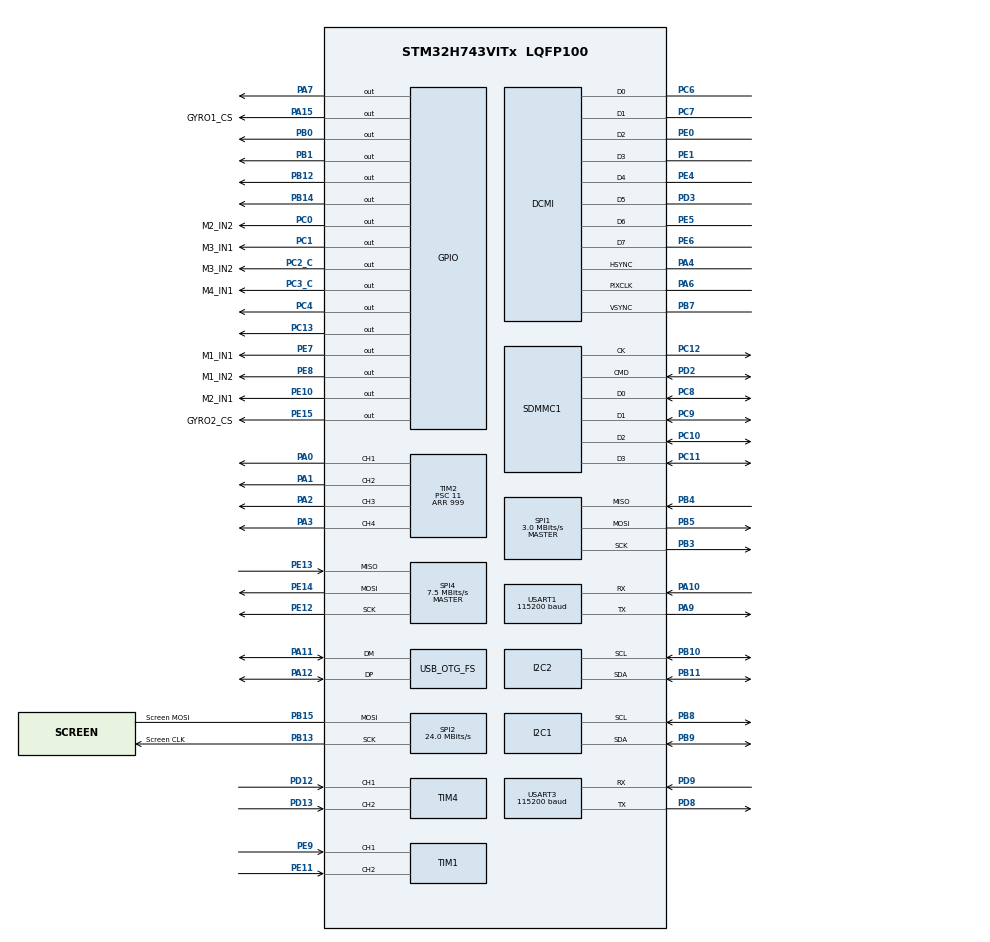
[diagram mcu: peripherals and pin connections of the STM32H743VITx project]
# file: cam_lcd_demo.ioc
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CORTEX_M7.CPU_DCache=Enabled
CORTEX_M7.CPU_ICache=Enabled
DCMI.JPEGMode=DCMI_JPEG_DISABLE
DCMI.PCKPolarity=DCMI_PCKPOLARITY_RISING
Dma.DCMI.0.Direction=DMA_PERIPH_TO_MEMORY
Dma.DCMI.0.EventEnable=DISABLE
Dma.DCMI.0.FIFOMode=DMA_FIFOMODE_ENABLE
Dma.DCMI.0.FIFOThreshold=DMA_FIFO_THRESHOLD_HALFFULL
Dma.DCMI.0.Instance=DMA1_Stream0
Dma.DCMI.0.MemBurst=DMA_MBURST_SINGLE
Dma.DCMI.0.MemDataAlignment=DMA_MDATAALIGN_WORD
Dma.DCMI.0.MemInc=DMA_MINC_ENABLE
Dma.DCMI.0.Mode=DMA_CIRCULAR
Dma.DCMI.0.PeriphBurst=DMA_PBURST_SINGLE
Dma.DCMI.0.PeriphDataAlignment=DMA_PDATAALIGN_WORD
Dma.DCMI.0.PeriphInc=DMA_PINC_DISABLE
Dma.DCMI.0.Polarity=HAL_DMAMUX_REQ_GEN_RISING
Dma.DCMI.0.Priority=DMA_PRIORITY_MEDIUM
Dma.DCMI.0.RequestNumber=1
Dma.DCMI.0.SignalID=NONE
Dma.DCMI.0.SyncEnable=DISABLE
Dma.DCMI.0.SyncPolarity=HAL_DMAMUX_SYNC_NO_EVENT
Dma.DCMI.0.SyncRequestNumber=1
Dma.DCMI.0.SyncSignalID=NONE
Dma.Request0=DCMI
FREERTOS.Tasks01=defaultTask,24,128,StartDefaultTask,Default,NULL,Dynamic,NULL,NULL
I2C1.Timing=0x307075B1
I2C2.Timing=0x307075B1
Mcu.Family=STM32H7
Mcu.Name=STM32H743VITx
Mcu.Package=LQFP100
NVIC.DCMI_IRQn=true\:5\:0\:true\:false\:true\:true\:true\:true\:true
NVIC.DMA1_Stream0_IRQn=true\:5\:0\:true\:false\:true\:true\:false\:true\:true
NVIC.I2C1_ER_IRQn=true\:5\:0\:false\:false\:true\:true\:true\:true\:true
NVIC.I2C1_EV_IRQn=true\:5\:0\:false\:false\:true\:true\:true\:true\:true
NVIC.I2C2_ER_IRQn=true\:5\:0\:false\:false\:true\:true\:true\:true\:true
NVIC.I2C2_EV_IRQn=true\:5\:0\:false\:false\:true\:true\:true\:true\:true
NVIC.OTG_FS_IRQn=true\:5\:0\:false\:false\:true\:true\:true\:true\:true
NVIC.PriorityGroup=NVIC_PRIORITYGROUP_4
NVIC.TIM6_DAC_IRQn=true\:15\:0\:false\:false\:true\:false\:false\:false\:true
NVIC.TimeBase=TIM6_DAC_IRQn
NVIC.TimeBaseIP=TIM6
NVIC.USART1_IRQn=true\:5\:0\:false\:false\:true\:true\:true\:true\:true
NVIC.USART3_IRQn=true\:5\:0\:false\:false\:true\:true\:true\:true\:true
PA0.Signal=S_TIM2_CH1_ETR
PA1.Signal=S_TIM2_CH2
PA10.Mode=Asynchronous
PA10.Signal=USART1_RX
PA11.Mode=Device_Only
PA11.Signal=USB_OTG_FS_DM
PA12.Mode=Device_Only
PA12.Signal=USB_OTG_FS_DP
PA13\ (JTMS/SWDIO).Mode=Trace_Asynchronous_SW
PA13\ (JTMS/SWDIO).Signal=DEBUG_JTMS-SWDIO
PA14\ (JTCK/SWCLK).Mode=Trace_Asynchronous_SW
PA14\ (JTCK/SWCLK).Signal=DEBUG_JTCK-SWCLK
PA15\ (JTDI).GPIO_Label=GYRO1_CS
PA15\ (JTDI).Signal=GPIO_Output
PA2.Signal=S_TIM2_CH3
PA3.Signal=S_TIM2_CH4
PA4.GPIO_PuPd=GPIO_PULLUP
PA4.GPIO_Speed=GPIO_SPEED_FREQ_VERY_HIGH
PA4.Mode=Slave_8_bits_External_Synchro
PA4.Signal=DCMI_HSYNC
PA6.GPIO_PuPd=GPIO_PULLUP
PA6.GPIO_Speed=GPIO_SPEED_FREQ_VERY_HIGH
PA6.Mode=Slave_8_bits_External_Synchro
PA6.Signal=DCMI_PIXCLK
PA7.GPIO_PuPd=GPIO_PULLUP
PA7.GPIO_Speed=GPIO_SPEED_FREQ_VERY_HIGH
PA7.PinState=GPIO_PIN_RESET
PA7.Signal=GPIO_Output
PA8.Signal=RCC_MCO_1
PA9.Mode=Asynchronous
PA9.Signal=USART1_TX
PB0.Signal=GPIO_Output
PB1.GPIO_PuPd=GPIO_PULLUP
PB1.GPIO_Speed=GPIO_SPEED_FREQ_VERY_HIGH
PB1.PinState=GPIO_PIN_SET
PB1.Signal=GPIO_Output
PB10.GPIO_Pu=GPIO_PULLUP
PB10.Mode=I2C
PB10.Signal=I2C2_SCL
PB11.GPIO_Pu=GPIO_PULLUP
PB11.Mode=I2C
PB11.Signal=I2C2_SDA
PB12.GPIO_PuPd=GPIO_PULLUP
PB12.GPIO_Speed=GPIO_SPEED_FREQ_VERY_HIGH
PB12.PinState=GPIO_PIN_SET
PB12.Signal=GPIO_Output
PB13.GPIO_Label=Screen CLK
PB13.Mode=Simplex_Bidirectional_Master
PB13.Signal=SPI2_SCK
PB14.GPIO_PuPd=GPIO_PULLUP
PB14.GPIO_Speed=GPIO_SPEED_FREQ_VERY_HIGH
PB14.PinState=GPIO_PIN_SET
PB14.Signal=GPIO_Output
PB15.GPIO_Label=Screen MOSI
PB15.Mode=Simplex_Bidirectional_Master
PB15.Signal=SPI2_MOSI
PB3\ (JTDO/TRACESWO).Mode=Full_Duplex_Master
PB3\ (JTDO/TRACESWO).Signal=SPI1_SCK
PB4\ (NJTRST).Mode=Full_Duplex_Master
PB4\ (NJTRST).Signal=SPI1_MISO
PB5.Mode=Full_Duplex_Master
PB5.Signal=SPI1_MOSI
PB7.GPIO_PuPd=GPIO_PULLUP
PB7.GPIO_Speed=GPIO_SPEED_FREQ_VERY_HIGH
PB7.Mode=Slave_8_bits_External_Synchro
PB7.Signal=DCMI_VSYNC
PB8.Mode=I2C
PB8.Signal=I2C1_SCL
PB9.Mode=I2C
PB9.Signal=I2C1_SDA
PC0.GPIO_Label=M2_IN2
PC0.Signal=GPIO_Output
PC1.GPIO_Label=M3_IN1
PC1.Signal=GPIO_Output
PC10.Mode=SD_4_bits_Wide_bus
PC10.Signal=SDMMC1_D2
PC11.Mode=SD_4_bits_Wide_bus
PC11.Signal=SDMMC1_D3
PC12.Mode=SD_4_bits_Wide_bus
PC12.Signal=SDMMC1_CK
PC13.Signal=GPIO_Output
PC2_C.GPIO_Label=M3_IN2
PC2_C.Signal=GPIO_Output
PC3_C.GPIO_Label=M4_IN1
PC3_C.Signal=GPIO_Output
PC4.GPIO_PuPd=GPIO_PULLUP
PC4.GPIO_Speed=GPIO_SPEED_FREQ_VERY_HIGH
PC4.PinState=GPIO_PIN_SET
PC4.Signal=GPIO_Output
PC6.GPIO_PuPd=GPIO_PULLUP
PC6.GPIO_Speed=GPIO_SPEED_FREQ_VERY_HIGH
PC6.Mode=Slave_8_bits_External_Synchro
PC6.Signal=DCMI_D0
PC7.GPIO_PuPd=GPIO_PULLUP
PC7.GPIO_Speed=GPIO_SPEED_FREQ_VERY_HIGH
PC7.Mode=Slave_8_bits_External_Synchro
PC7.Signal=DCMI_D1
PC8.Mode=SD_4_bits_Wide_bus
PC8.Signal=SDMMC1_D0
PC9.Mode=SD_4_bits_Wide_bus
PC9.Signal=SDMMC1_D1
PD12.Signal=S_TIM4_CH1
PD13.Signal=S_TIM4_CH2
PD2.Mode=SD_4_bits_Wide_bus
PD2.Signal=SDMMC1_CMD
PD3.GPIO_PuPd=GPIO_PULLUP
PD3.GPIO_Speed=GPIO_SPEED_FREQ_VERY_HIGH
PD3.Mode=Slave_8_bits_External_Synchro
PD3.Signal=DCMI_D5
PD8.Mode=Asynchronous
PD8.Signal=USART3_TX
PD9.Mode=Asynchronous
PD9.Signal=USART3_RX
PE0.GPIO_PuPd=GPIO_PULLUP
PE0.GPIO_Speed=GPIO_SPEED_FREQ_VERY_HIGH
PE0.Mode=Slave_8_bits_External_Synchro
PE0.Signal=DCMI_D2
PE1.GPIO_PuPd=GPIO_PULLUP
PE1.GPIO_Speed=GPIO_SPEED_FREQ_VERY_HIGH
PE1.Mode=Slave_8_bits_External_Synchro
PE1.Signal=DCMI_D3
PE10.GPIO_Label=M2_IN1
PE10.Signal=GPIO_Output
PE11.Signal=S_TIM1_CH2
PE12.Mode=Full_Duplex_Master
PE12.Signal=SPI4_SCK
PE13.Mode=Full_Duplex_Master
PE13.Signal=SPI4_MISO
PE14.Mode=Full_Duplex_Master
PE14.Signal=SPI4_MOSI
PE15.GPIO_Label=GYRO2_CS
PE15.Signal=GPIO_Output
PE4.GPIO_PuPd=GPIO_PULLUP
PE4.GPIO_Speed=GPIO_SPEED_FREQ_VERY_HIGH
PE4.Mode=Slave_8_bits_External_Synchro
PE4.Signal=DCMI_D4
PE5.GPIO_PuPd=GPIO_PULLUP
PE5.GPIO_Speed=GPIO_SPEED_FREQ_VERY_HIGH
PE5.Mode=Slave_8_bits_External_Synchro
PE5.Signal=DCMI_D6
PE6.GPIO_PuPd=GPIO_PULLUP
PE6.GPIO_Speed=GPIO_SPEED_FREQ_VERY_HIGH
PE6.Mode=Slave_8_bits_External_Synchro
PE6.Signal=DCMI_D7
PE7.GPIO_Label=M1_IN1
PE7.Signal=GPIO_Output
PE8.GPIO_Label=M1_IN2
PE8.Signal=GPIO_Output
PE9.Signal=S_TIM1_CH1
PH0-OSC_IN\ (PH0).Mode=HSE-External-Clock-Source
PH0-OSC_IN\ (PH0).Signal=RCC_OSC_IN
PH1-OSC_OUT\ (PH1).Signal=RCC_OSC_OUT
ProjectManager.HeapSize=0x800
ProjectManager.StackSize=0x1000
ProjectManager.TargetToolchain=CMake
RCC.48MHZClocksFreq_Value=48000000
RCC.ADCFreq_Value=50390625
RCC.AHBFreq_Value=240000000
RCC.APB1Freq_Value=120000000
RCC.APB1TimFreq_Value=240000000
RCC.APB2Freq_Value=120000000
RCC.APB2TimFreq_Value=240000000
RCC.APB3Freq_Value=120000000
RCC.APB4Freq_Value=120000000
RCC.CKPERSourceSelection=RCC_CLKPSOURCE_HSE
RCC.CortexFreq_Value=480000000
RCC.D1PPRE=RCC_APB3_DIV2
RCC.D2PPRE1=RCC_APB1_DIV2
RCC.D2PPRE2=RCC_APB2_DIV2
RCC.D3PPRE=RCC_APB4_DIV2
RCC.DIVM1=5
RCC.DIVN1=192
RCC.DIVQ1=20
RCC.DIVR1=2
RCC.HCLKFreq_Value=240000000
RCC.HPRE=RCC_HCLK_DIV2
RCC.HSE_VALUE=25000000
RCC.HSI_VALUE=64000000
RCC.PLLFRACN=0
RCC.PLLSourceVirtual=RCC_PLLSOURCE_HSE
RCC.PWR_Regulator_Voltage_Scale=PWR_REGULATOR_VOLTAGE_SCALE0
RCC.RCC_MCO1Source=RCC_MCO1SOURCE_HSE
RCC.SYSCLKFreq_VALUE=480000000
RCC.SYSCLKSource=RCC_SYSCLKSOURCE_PLLCLK
RCC.SYSCLKSourceVirtual=RCC_SYSCLKSOURCE_PLLCLK
RCC.USBCLockSelection=RCC_USBCLKSOURCE_PLL
RCC.USBFreq_Value=48000000
SH.S_TIM1_CH1.0=TIM1_CH1,Encoder_Interface
SH.S_TIM1_CH2.0=TIM1_CH2,Encoder_Interface
SH.S_TIM2_CH1_ETR.0=TIM2_CH1,PWM Generation1 CH1
SH.S_TIM2_CH2.0=TIM2_CH2,PWM Generation2 CH2
SH.S_TIM2_CH3.0=TIM2_CH3,PWM Generation3 CH3
SH.S_TIM2_CH4.0=TIM2_CH4,PWM Generation4 CH4
SH.S_TIM4_CH1.0=TIM4_CH1,Encoder_Interface
SH.S_TIM4_CH2.0=TIM4_CH2,Encoder_Interface
SPI1.BaudRatePrescaler=SPI_BAUDRATEPRESCALER_16
SPI1.CalculateBaudRate=3.0 MBits/s
SPI1.DataSize=SPI_DATASIZE_8BIT
SPI1.Direction=SPI_DIRECTION_2LINES
SPI1.Mode=SPI_MODE_MASTER
SPI1.VirtualMode=Full-Duplex_Master
SPI1.VirtualType=VM_MASTER
SPI2.CalculateBaudRate=24.0 MBits/s
SPI2.DataSize=SPI_DATASIZE_8BIT
SPI2.Direction=SPI_DIRECTION_1LINE
SPI2.Mode=SPI_MODE_MASTER
SPI2.VirtualType=VM_MASTER
SPI4.BaudRatePrescaler=SPI_BAUDRATEPRESCALER_16
SPI4.CalculateBaudRate=7.5 MBits/s
SPI4.DataSize=SPI_DATASIZE_8BIT
SPI4.Direction=SPI_DIRECTION_2LINES
SPI4.Mode=SPI_MODE_MASTER
SPI4.VirtualMode=Full-Duplex_Master
SPI4.VirtualType=VM_MASTER
TIM2.AutoReloadPreload=TIM_AUTORELOAD_PRELOAD_DISABLE
TIM2.Channel-PWM\ Generation1\ CH1=TIM_CHANNEL_1
TIM2.Channel-PWM\ Generation2\ CH2=TIM_CHANNEL_2
TIM2.Channel-PWM\ Generation3\ CH3=TIM_CHANNEL_3
TIM2.Channel-PWM\ Generation4\ CH4=TIM_CHANNEL_4
TIM2.ClockDivision=TIM_CLOCKDIVISION_DIV1
TIM2.CounterMode=TIM_COUNTERMODE_UP
TIM2.Period=999
TIM2.Prescaler=11
USART1.BaudRate=115200
USART1.Parity=PARITY_NONE
USART1.StopBits=STOPBITS_1
USART1.VirtualMode-Asynchronous=VM_ASYNC
USART1.WordLength=WORDLENGTH_8B
USART3.BaudRate=115200
USART3.FIFOMode=FIFOMODE_DISABLE
USART3.OneBitSampling=UART_ONE_BIT_SAMPLE_ENABLE
USART3.Parity=PARITY_NONE
USART3.StopBits=STOPBITS_1
USART3.VirtualMode-Asynchronous=VM_ASYNC
USART3.WordLength=WORDLENGTH_8B
USB_DEVICE.CLASS_NAME_FS=CDC
USB_DEVICE.USBD_LPM_ENABLED-CDC_FS=0
USB_DEVICE.VirtualMode-CDC_FS=Cdc
USB_DEVICE.VirtualModeFS=Cdc_FS
USB_OTG_FS.VirtualMode=Device_Only
VP_FREERTOS_VS_CMSIS_V2.Mode=CMSIS_V2
VP_MEMORYMAP_VS_MEMORYMAP.Mode=CurAppReg
VP_SYS_VS_tim6.Mode=TIM6
VP_TIM2_VS_ClockSourceINT.Mode=Internal
VP_USB_DEVICE_VS_USB_DEVICE_CDC_FS.Mode=CDC_FS
board=custom

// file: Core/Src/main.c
/* USER CODE BEGIN Header */
/**
  ******************************************************************************
  * @file           : main.c
  * @brief          : ��10 ��Ļ��ʾ����ͷ (OV2640 RGB565 -> 1.44�� LCD)
  ******************************************************************************
  */
/* USER CODE END Header */
#include "main.h"
#include "FreeRTOS.h"
#include "cmsis_os2.h"
#include "usb_device.h"

/* USER CODE BEGIN Includes */
#include "usb_vcp.h"
#include "cam_lcd.h"
#include "app_config.h"
#include "vision_task.h"
/* USER CODE END Includes */

DCMI_HandleTypeDef hdcmi;
DMA_HandleTypeDef hdma_dcmi;

I2C_HandleTypeDef hi2c1;
I2C_HandleTypeDef hi2c2;

SD_HandleTypeDef hsd1;

SPI_HandleTypeDef hspi1;
SPI_HandleTypeDef hspi2;
SPI_HandleTypeDef hspi4;

TIM_HandleTypeDef htim1;
TIM_HandleTypeDef htim2;
TIM_HandleTypeDef htim4;

UART_HandleTypeDef huart1;
UART_HandleTypeDef huart3;

/* Definitions for defaultTask */
osThreadId_t defaultTaskHandle;
const osThreadAttr_t defaultTask_attributes = {
  .name = "defaultTask",
  .stack_size = 1024 * 8,
  .priority = (osPriority_t) osPriorityNormal,
};

void SystemClock_Config(void);
static void MX_GPIO_Init(void);
static void MX_DMA_Init(void);
static void MX_I2C1_Init(void);
static void MX_I2C2_Init(void);
static void MX_SPI1_Init(void);
static void MX_SPI4_Init(void);
static void MX_TIM1_Init(void);
static void MX_TIM2_Init(void);
static void MX_TIM4_Init(void);
static void MX_USART1_UART_Init(void);
static void MX_USART3_UART_Init(void);
static void MX_DCMI_Init(void);
static void MX_SDMMC1_SD_Init(void);
static void MX_SPI2_Init(void);
void StartDefaultTask(void *argument);

int main(void)
{

  /* Enable the CPU Cache */

  /* Enable I-Cache---------------------------------------------------------*/
  SCB_EnableICache();

  /* Enable D-Cache---------------------------------------------------------*/
  SCB_EnableDCache();

  /* MCU Configuration--------------------------------------------------------*/

  /* Reset of all peripherals, Initializes the Flash interface and the Systick. */
  HAL_Init();

  /* Configure the system clock */
  SystemClock_Config();

  /* Initialize all configured peripherals */
  MX_GPIO_Init();
  MX_DMA_Init();
  MX_I2C1_Init();
  MX_I2C2_Init();
  MX_SPI1_Init();
  MX_SPI4_Init();
  MX_TIM1_Init();
  MX_TIM2_Init();
  MX_TIM4_Init();
  MX_USART1_UART_Init();
  MX_USART3_UART_Init();
  MX_DCMI_Init();
  MX_SDMMC1_SD_Init();
  MX_SPI2_Init();

  /* Init scheduler */
  osKernelInitialize();

  /* USER CODE BEGIN RTOS_QUEUES */
  if (!UsbVcp_Init())
  {
    Error_Handler();
  }
  /* USER CODE END RTOS_QUEUES */

  /* Create the thread(s) */
  /* creation of defaultTask */
  defaultTaskHandle = osThreadNew(StartDefaultTask, NULL, &defaultTask_attributes);

  /* Start scheduler */
  osKernelStart();

  /* We should never get here as control is now taken by the scheduler */

  /* Infinite loop */
  while (1)
  {

  }
}

void SystemClock_Config(void)
{
  RCC_OscInitTypeDef RCC_OscInitStruct = {0};
  RCC_ClkInitTypeDef RCC_ClkInitStruct = {0};

  /** Supply configuration update enable
  */
  HAL_PWREx_ConfigSupply(PWR_LDO_SUPPLY);

  /** Configure the main internal regulator output voltage
  */
  __HAL_PWR_VOLTAGESCALING_CONFIG(PWR_REGULATOR_VOLTAGE_SCALE0);

  while(!__HAL_PWR_GET_FLAG(PWR_FLAG_VOSRDY)) {}

  /** Initializes the RCC Oscillators according to the specified parameters
  * in the RCC_OscInitTypeDef structure.
  */
  RCC_OscInitStruct.OscillatorType = RCC_OSCILLATORTYPE_HSE;
  RCC_OscInitStruct.HSEState = RCC_HSE_BYPASS;
  RCC_OscInitStruct.PLL.PLLState = RCC_PLL_ON;
  RCC_OscInitStruct.PLL.PLLSource = RCC_PLLSOURCE_HSE;
  RCC_OscInitStruct.PLL.PLLM = 5;
  RCC_OscInitStruct.PLL.PLLN = 192;
  RCC_OscInitStruct.PLL.PLLP = 2;
  RCC_OscInitStruct.PLL.PLLQ = 20;
  RCC_OscInitStruct.PLL.PLLR = 2;
  RCC_OscInitStruct.PLL.PLLRGE = RCC_PLL1VCIRANGE_2;
  RCC_OscInitStruct.PLL.PLLVCOSEL = RCC_PLL1VCOWIDE;
  RCC_OscInitStruct.PLL.PLLFRACN = 0;
  if (HAL_RCC_OscConfig(&RCC_OscInitStruct) != HAL_OK)
  {
    Error_Handler();
  }

  /** Initializes the CPU, AHB and APB buses clocks
  */
  RCC_ClkInitStruct.ClockType = RCC_CLOCKTYPE_HCLK|RCC_CLOCKTYPE_SYSCLK
                              |RCC_CLOCKTYPE_PCLK1|RCC_CLOCKTYPE_PCLK2
                              |RCC_CLOCKTYPE_D3PCLK1|RCC_CLOCKTYPE_D1PCLK1;
  RCC_ClkInitStruct.SYSCLKSource = RCC_SYSCLKSOURCE_PLLCLK;
  RCC_ClkInitStruct.SYSCLKDivider = RCC_SYSCLK_DIV1;
  RCC_ClkInitStruct.AHBCLKDivider = RCC_HCLK_DIV2;
  RCC_ClkInitStruct.APB3CLKDivider = RCC_APB3_DIV2;
  RCC_ClkInitStruct.APB1CLKDivider = RCC_APB1_DIV2;
  RCC_ClkInitStruct.APB2CLKDivider = RCC_APB2_DIV2;
  RCC_ClkInitStruct.APB4CLKDivider = RCC_APB4_DIV2;

  if (HAL_RCC_ClockConfig(&RCC_ClkInitStruct, FLASH_LATENCY_4) != HAL_OK)
  {
    Error_Handler();
  }
}

static void MX_DCMI_Init(void)
{

  hdcmi.Instance = DCMI;
  hdcmi.Init.SynchroMode = DCMI_SYNCHRO_HARDWARE;
  hdcmi.Init.PCKPolarity = DCMI_PCKPOLARITY_RISING;
  hdcmi.Init.VSPolarity = DCMI_VSPOLARITY_LOW;
  hdcmi.Init.HSPolarity = DCMI_HSPOLARITY_LOW;
  hdcmi.Init.CaptureRate = DCMI_CR_ALL_FRAME;
  hdcmi.Init.ExtendedDataMode = DCMI_EXTEND_DATA_8B;
  hdcmi.Init.JPEGMode = DCMI_JPEG_DISABLE;
  hdcmi.Init.ByteSelectMode = DCMI_BSM_ALL;
  hdcmi.Init.ByteSelectStart = DCMI_OEBS_ODD;
  hdcmi.Init.LineSelectMode = DCMI_LSM_ALL;
  hdcmi.Init.LineSelectStart = DCMI_OELS_ODD;
  if (HAL_DCMI_Init(&hdcmi) != HAL_OK)
  {
    Error_Handler();
  }

}

static void MX_I2C1_Init(void)
{

  hi2c1.Instance = I2C1;
  hi2c1.Init.Timing = 0x307075B1;
  hi2c1.Init.OwnAddress1 = 0;
  hi2c1.Init.AddressingMode = I2C_ADDRESSINGMODE_7BIT;
  hi2c1.Init.DualAddressMode = I2C_DUALADDRESS_DISABLE;
  hi2c1.Init.OwnAddress2 = 0;
  hi2c1.Init.OwnAddress2Masks = I2C_OA2_NOMASK;
  hi2c1.Init.GeneralCallMode = I2C_GENERALCALL_DISABLE;
  hi2c1.Init.NoStretchMode = I2C_NOSTRETCH_DISABLE;
  if (HAL_I2C_Init(&hi2c1) != HAL_OK)
  {
    Error_Handler();
  }

  /** Configure Analogue filter
  */
  if (HAL_I2CEx_ConfigAnalogFilter(&hi2c1, I2C_ANALOGFILTER_ENABLE) != HAL_OK)
  {
    Error_Handler();
  }

  /** Configure Digital filter
  */
  if (HAL_I2CEx_ConfigDigitalFilter(&hi2c1, 0) != HAL_OK)
  {
    Error_Handler();
  }

}

static void MX_I2C2_Init(void)
{

  hi2c2.Instance = I2C2;
  hi2c2.Init.Timing = 0x307075B1;
  hi2c2.Init.OwnAddress1 = 0;
  hi2c2.Init.AddressingMode = I2C_ADDRESSINGMODE_7BIT;
  hi2c2.Init.DualAddressMode = I2C_DUALADDRESS_DISABLE;
  hi2c2.Init.OwnAddress2 = 0;
  hi2c2.Init.OwnAddress2Masks = I2C_OA2_NOMASK;
  hi2c2.Init.GeneralCallMode = I2C_GENERALCALL_DISABLE;
  hi2c2.Init.NoStretchMode = I2C_NOSTRETCH_DISABLE;
  if (HAL_I2C_Init(&hi2c2) != HAL_OK)
  {
    Error_Handler();
  }

  /** Configure Analogue filter
  */
  if (HAL_I2CEx_ConfigAnalogFilter(&hi2c2, I2C_ANALOGFILTER_ENABLE) != HAL_OK)
  {
    Error_Handler();
  }

  /** Configure Digital filter
  */
  if (HAL_I2CEx_ConfigDigitalFilter(&hi2c2, 0) != HAL_OK)
  {
    Error_Handler();
  }

}

static void MX_SDMMC1_SD_Init(void)
{

  hsd1.Instance = SDMMC1;
  hsd1.Init.ClockEdge = SDMMC_CLOCK_EDGE_RISING;
  hsd1.Init.ClockPowerSave = SDMMC_CLOCK_POWER_SAVE_DISABLE;
  hsd1.Init.BusWide = SDMMC_BUS_WIDE_4B;
  hsd1.Init.HardwareFlowControl = SDMMC_HARDWARE_FLOW_CONTROL_DISABLE;
  hsd1.Init.ClockDiv = 0;
  if (HAL_SD_Init(&hsd1) != HAL_OK)
  {
    Error_Handler();
  }

}

static void MX_SPI1_Init(void)
{

  /* SPI1 parameter configuration*/
  hspi1.Instance = SPI1;
  hspi1.Init.Mode = SPI_MODE_MASTER;
  hspi1.Init.Direction = SPI_DIRECTION_2LINES;
  hspi1.Init.DataSize = SPI_DATASIZE_8BIT;
  hspi1.Init.CLKPolarity = SPI_POLARITY_LOW;
  hspi1.Init.CLKPhase = SPI_PHASE_1EDGE;
  hspi1.Init.NSS = SPI_NSS_SOFT;
  hspi1.Init.BaudRatePrescaler = SPI_BAUDRATEPRESCALER_16;
  hspi1.Init.FirstBit = SPI_FIRSTBIT_MSB;
  hspi1.Init.TIMode = SPI_TIMODE_DISABLE;
  hspi1.Init.CRCCalculation = SPI_CRCCALCULATION_DISABLE;
  hspi1.Init.CRCPolynomial = 0x0;
  hspi1.Init.NSSPMode = SPI_NSS_PULSE_ENABLE;
  hspi1.Init.NSSPolarity = SPI_NSS_POLARITY_LOW;
  hspi1.Init.FifoThreshold = SPI_FIFO_THRESHOLD_01DATA;
  hspi1.Init.TxCRCInitializationPattern = SPI_CRC_INITIALIZATION_ALL_ZERO_PATTERN;
  hspi1.Init.RxCRCInitializationPattern = SPI_CRC_INITIALIZATION_ALL_ZERO_PATTERN;
  hspi1.Init.MasterSSIdleness = SPI_MASTER_SS_IDLENESS_00CYCLE;
  hspi1.Init.MasterInterDataIdleness = SPI_MASTER_INTERDATA_IDLENESS_00CYCLE;
  hspi1.Init.MasterReceiverAutoSusp = SPI_MASTER_RX_AUTOSUSP_DISABLE;
  hspi1.Init.MasterKeepIOState = SPI_MASTER_KEEP_IO_STATE_DISABLE;
  hspi1.Init.IOSwap = SPI_IO_SWAP_DISABLE;
  if (HAL_SPI_Init(&hspi1) != HAL_OK)
  {
    Error_Handler();
  }

}

static void MX_SPI2_Init(void)
{

  /* SPI2 parameter configuration*/
  hspi2.Instance = SPI2;
  hspi2.Init.Mode = SPI_MODE_MASTER;
  hspi2.Init.Direction = SPI_DIRECTION_1LINE;
  hspi2.Init.DataSize = SPI_DATASIZE_8BIT;
  hspi2.Init.CLKPolarity = SPI_POLARITY_LOW;
  hspi2.Init.CLKPhase = SPI_PHASE_1EDGE;
  hspi2.Init.NSS = SPI_NSS_SOFT;
  hspi2.Init.BaudRatePrescaler = SPI_BAUDRATEPRESCALER_2;
  hspi2.Init.FirstBit = SPI_FIRSTBIT_MSB;
  hspi2.Init.TIMode = SPI_TIMODE_DISABLE;
  hspi2.Init.CRCCalculation = SPI_CRCCALCULATION_DISABLE;
  hspi2.Init.CRCPolynomial = 0x0;
  hspi2.Init.NSSPMode = SPI_NSS_PULSE_ENABLE;
  hspi2.Init.NSSPolarity = SPI_NSS_POLARITY_LOW;
  hspi2.Init.FifoThreshold = SPI_FIFO_THRESHOLD_01DATA;
  hspi2.Init.TxCRCInitializationPattern = SPI_CRC_INITIALIZATION_ALL_ZERO_PATTERN;
  hspi2.Init.RxCRCInitializationPattern = SPI_CRC_INITIALIZATION_ALL_ZERO_PATTERN;
  hspi2.Init.MasterSSIdleness = SPI_MASTER_SS_IDLENESS_00CYCLE;
  hspi2.Init.MasterInterDataIdleness = SPI_MASTER_INTERDATA_IDLENESS_00CYCLE;
  hspi2.Init.MasterReceiverAutoSusp = SPI_MASTER_RX_AUTOSUSP_DISABLE;
  hspi2.Init.MasterKeepIOState = SPI_MASTER_KEEP_IO_STATE_DISABLE;
  hspi2.Init.IOSwap = SPI_IO_SWAP_DISABLE;
  if (HAL_SPI_Init(&hspi2) != HAL_OK)
  {
    Error_Handler();
  }

}

static void MX_SPI4_Init(void)
{

  /* SPI4 parameter configuration*/
  hspi4.Instance = SPI4;
  hspi4.Init.Mode = SPI_MODE_MASTER;
  hspi4.Init.Direction = SPI_DIRECTION_2LINES;
  hspi4.Init.DataSize = SPI_DATASIZE_8BIT;
  hspi4.Init.CLKPolarity = SPI_POLARITY_LOW;
  hspi4.Init.CLKPhase = SPI_PHASE_1EDGE;
  hspi4.Init.NSS = SPI_NSS_SOFT;
  hspi4.Init.BaudRatePrescaler = SPI_BAUDRATEPRESCALER_16;
  hspi4.Init.FirstBit = SPI_FIRSTBIT_MSB;
  hspi4.Init.TIMode = SPI_TIMODE_DISABLE;
  hspi4.Init.CRCCalculation = SPI_CRCCALCULATION_DISABLE;
  hspi4.Init.CRCPolynomial = 0x0;
  hspi4.Init.NSSPMode = SPI_NSS_PULSE_ENABLE;
  hspi4.Init.NSSPolarity = SPI_NSS_POLARITY_LOW;
  hspi4.Init.FifoThreshold = SPI_FIFO_THRESHOLD_01DATA;
  hspi4.Init.TxCRCInitializationPattern = SPI_CRC_INITIALIZATION_ALL_ZERO_PATTERN;
  hspi4.Init.RxCRCInitializationPattern = SPI_CRC_INITIALIZATION_ALL_ZERO_PATTERN;
  hspi4.Init.MasterSSIdleness = SPI_MASTER_SS_IDLENESS_00CYCLE;
  hspi4.Init.MasterInterDataIdleness = SPI_MASTER_INTERDATA_IDLENESS_00CYCLE;
  hspi4.Init.MasterReceiverAutoSusp = SPI_MASTER_RX_AUTOSUSP_DISABLE;
  hspi4.Init.MasterKeepIOState = SPI_MASTER_KEEP_IO_STATE_DISABLE;
  hspi4.Init.IOSwap = SPI_IO_SWAP_DISABLE;
  if (HAL_SPI_Init(&hspi4) != HAL_OK)
  {
    Error_Handler();
  }

}

static void MX_TIM1_Init(void)
{

  TIM_Encoder_InitTypeDef sConfig = {0};
  TIM_MasterConfigTypeDef sMasterConfig = {0};

  htim1.Instance = TIM1;
  htim1.Init.Prescaler = 0;
  htim1.Init.CounterMode = TIM_COUNTERMODE_UP;
  htim1.Init.Period = 65535;
  htim1.Init.ClockDivision = TIM_CLOCKDIVISION_DIV1;
  htim1.Init.RepetitionCounter = 0;
  htim1.Init.AutoReloadPreload = TIM_AUTORELOAD_PRELOAD_DISABLE;
  sConfig.EncoderMode = TIM_ENCODERMODE_TI1;
  sConfig.IC1Polarity = TIM_ICPOLARITY_RISING;
  sConfig.IC1Selection = TIM_ICSELECTION_DIRECTTI;
  sConfig.IC1Prescaler = TIM_ICPSC_DIV1;
  sConfig.IC1Filter = 0;
  sConfig.IC2Polarity = TIM_ICPOLARITY_RISING;
  sConfig.IC2Selection = TIM_ICSELECTION_DIRECTTI;
  sConfig.IC2Prescaler = TIM_ICPSC_DIV1;
  sConfig.IC2Filter = 0;
  if (HAL_TIM_Encoder_Init(&htim1, &sConfig) != HAL_OK)
  {
    Error_Handler();
  }
  sMasterConfig.MasterOutputTrigger = TIM_TRGO_RESET;
  sMasterConfig.MasterOutputTrigger2 = TIM_TRGO2_RESET;
  sMasterConfig.MasterSlaveMode = TIM_MASTERSLAVEMODE_DISABLE;
  if (HAL_TIMEx_MasterConfigSynchronization(&htim1, &sMasterConfig) != HAL_OK)
  {
    Error_Handler();
  }

}

static void MX_TIM2_Init(void)
{

  TIM_ClockConfigTypeDef sClockSourceConfig = {0};
  TIM_MasterConfigTypeDef sMasterConfig = {0};
  TIM_OC_InitTypeDef sConfigOC = {0};

  htim2.Instance = TIM2;
  htim2.Init.Prescaler = 11;
  htim2.Init.CounterMode = TIM_COUNTERMODE_UP;
  htim2.Init.Period = 999;
  htim2.Init.ClockDivision = TIM_CLOCKDIVISION_DIV1;
  htim2.Init.AutoReloadPreload = TIM_AUTORELOAD_PRELOAD_DISABLE;
  if (HAL_TIM_Base_Init(&htim2) != HAL_OK)
  {
    Error_Handler();
  }
  sClockSourceConfig.ClockSource = TIM_CLOCKSOURCE_INTERNAL;
  if (HAL_TIM_ConfigClockSource(&htim2, &sClockSourceConfig) != HAL_OK)
  {
    Error_Handler();
  }
  if (HAL_TIM_PWM_Init(&htim2) != HAL_OK)
  {
    Error_Handler();
  }
  sMasterConfig.MasterOutputTrigger = TIM_TRGO_RESET;
  sMasterConfig.MasterSlaveMode = TIM_MASTERSLAVEMODE_DISABLE;
  if (HAL_TIMEx_MasterConfigSynchronization(&htim2, &sMasterConfig) != HAL_OK)
  {
    Error_Handler();
  }
  sConfigOC.OCMode = TIM_OCMODE_PWM1;
  sConfigOC.Pulse = 0;
  sConfigOC.OCPolarity = TIM_OCPOLARITY_HIGH;
  sConfigOC.OCFastMode = TIM_OCFAST_DISABLE;
  if (HAL_TIM_PWM_ConfigChannel(&htim2, &sConfigOC, TIM_CHANNEL_1) != HAL_OK)
  {
    Error_Handler();
  }
  if (HAL_TIM_PWM_ConfigChannel(&htim2, &sConfigOC, TIM_CHANNEL_2) != HAL_OK)
  {
    Error_Handler();
  }
  if (HAL_TIM_PWM_ConfigChannel(&htim2, &sConfigOC, TIM_CHANNEL_3) != HAL_OK)
  {
    Error_Handler();
  }
  if (HAL_TIM_PWM_ConfigChannel(&htim2, &sConfigOC, TIM_CHANNEL_4) != HAL_OK)
  {
    Error_Handler();
  }
  HAL_TIM_MspPostInit(&htim2);

}

static void MX_TIM4_Init(void)
{

  TIM_Encoder_InitTypeDef sConfig = {0};
  TIM_MasterConfigTypeDef sMasterConfig = {0};

  htim4.Instance = TIM4;
  htim4.Init.Prescaler = 0;
  htim4.Init.CounterMode = TIM_COUNTERMODE_UP;
  htim4.Init.Period = 65535;
  htim4.Init.ClockDivision = TIM_CLOCKDIVISION_DIV1;
  htim4.Init.AutoReloadPreload = TIM_AUTORELOAD_PRELOAD_DISABLE;
  sConfig.EncoderMode = TIM_ENCODERMODE_TI1;
  sConfig.IC1Polarity = TIM_ICPOLARITY_RISING;
  sConfig.IC1Selection = TIM_ICSELECTION_DIRECTTI;
  sConfig.IC1Prescaler = TIM_ICPSC_DIV1;
  sConfig.IC1Filter = 0;
  sConfig.IC2Polarity = TIM_ICPOLARITY_RISING;
  sConfig.IC2Selection = TIM_ICSELECTION_DIRECTTI;
  sConfig.IC2Prescaler = TIM_ICPSC_DIV1;
  sConfig.IC2Filter = 0;
  if (HAL_TIM_Encoder_Init(&htim4, &sConfig) != HAL_OK)
  {
    Error_Handler();
  }
  sMasterConfig.MasterOutputTrigger = TIM_TRGO_RESET;
  sMasterConfig.MasterSlaveMode = TIM_MASTERSLAVEMODE_DISABLE;
  if (HAL_TIMEx_MasterConfigSynchronization(&htim4, &sMasterConfig) != HAL_OK)
  {
    Error_Handler();
  }

}

static void MX_USART1_UART_Init(void)
{

  huart1.Instance = USART1;
  huart1.Init.BaudRate = 115200;
  huart1.Init.WordLength = UART_WORDLENGTH_8B;
  huart1.Init.StopBits = UART_STOPBITS_1;
  huart1.Init.Parity = UART_PARITY_NONE;
  huart1.Init.Mode = UART_MODE_TX_RX;
  huart1.Init.HwFlowCtl = UART_HWCONTROL_NONE;
  huart1.Init.OverSampling = UART_OVERSAMPLING_16;
  huart1.Init.OneBitSampling = UART_ONE_BIT_SAMPLE_DISABLE;
  huart1.Init.ClockPrescaler = UART_PRESCALER_DIV1;
  huart1.AdvancedInit.AdvFeatureInit = UART_ADVFEATURE_NO_INIT;
  if (HAL_UART_Init(&huart1) != HAL_OK)
  {
    Error_Handler();
  }
  if (HAL_UARTEx_SetTxFifoThreshold(&huart1, UART_TXFIFO_THRESHOLD_1_8) != HAL_OK)
  {
    Error_Handler();
  }
  if (HAL_UARTEx_SetRxFifoThreshold(&huart1, UART_RXFIFO_THRESHOLD_1_8) != HAL_OK)
  {
    Error_Handler();
  }
  if (HAL_UARTEx_DisableFifoMode(&huart1) != HAL_OK)
  {
    Error_Handler();
  }

}

static void MX_USART3_UART_Init(void)
{

  huart3.Instance = USART3;
  huart3.Init.BaudRate = 115200;
  huart3.Init.WordLength = UART_WORDLENGTH_8B;
  huart3.Init.StopBits = UART_STOPBITS_1;
  huart3.Init.Parity = UART_PARITY_NONE;
  huart3.Init.Mode = UART_MODE_TX_RX;
  huart3.Init.HwFlowCtl = UART_HWCONTROL_NONE;
  huart3.Init.OverSampling = UART_OVERSAMPLING_16;
  huart3.Init.OneBitSampling = UART_ONE_BIT_SAMPLE_ENABLE;
  huart3.Init.ClockPrescaler = UART_PRESCALER_DIV1;
  huart3.AdvancedInit.AdvFeatureInit = UART_ADVFEATURE_NO_INIT;
  if (HAL_UART_Init(&huart3) != HAL_OK)
  {
    Error_Handler();
  }
  if (HAL_UARTEx_SetTxFifoThreshold(&huart3, UART_TXFIFO_THRESHOLD_1_8) != HAL_OK)
  {
    Error_Handler();
  }
  if (HAL_UARTEx_SetRxFifoThreshold(&huart3, UART_RXFIFO_THRESHOLD_1_8) != HAL_OK)
  {
    Error_Handler();
  }
  if (HAL_UARTEx_DisableFifoMode(&huart3) != HAL_OK)
  {
    Error_Handler();
  }

}

static void MX_DMA_Init(void)
{

  /* DMA controller clock enable */
  __HAL_RCC_DMA1_CLK_ENABLE();

  /* DMA interrupt init */
  /* DMA1_Stream0_IRQn interrupt configuration */
  HAL_NVIC_SetPriority(DMA1_Stream0_IRQn, 5, 0);
  HAL_NVIC_EnableIRQ(DMA1_Stream0_IRQn);

}

static void MX_GPIO_Init(void)
{
  GPIO_InitTypeDef GPIO_InitStruct = {0};

  /* GPIO Ports Clock Enable */
  __HAL_RCC_GPIOE_CLK_ENABLE();
  __HAL_RCC_GPIOC_CLK_ENABLE();
  __HAL_RCC_GPIOH_CLK_ENABLE();
  __HAL_RCC_GPIOA_CLK_ENABLE();
  __HAL_RCC_GPIOB_CLK_ENABLE();
  __HAL_RCC_GPIOD_CLK_ENABLE();

  /*Configure GPIO pin Output Level */
  HAL_GPIO_WritePin(GPIOC, GPIO_PIN_13|M2_IN2_Pin|M3_IN1_Pin|M3_IN2_Pin
                          |M4_IN1_Pin, GPIO_PIN_RESET);

  /*Configure GPIO pin Output Level */
  HAL_GPIO_WritePin(GPIOA, GPIO_PIN_7|GYRO1_CS_Pin, GPIO_PIN_RESET);

  /*Configure GPIO pin Output Level */
  HAL_GPIO_WritePin(GPIOC, GPIO_PIN_4, GPIO_PIN_SET);

  /*Configure GPIO pin Output Level */
  HAL_GPIO_WritePin(GPIOB, GPIO_PIN_0, GPIO_PIN_RESET);

  /*Configure GPIO pin Output Level */
  HAL_GPIO_WritePin(GPIOB, GPIO_PIN_1|GPIO_PIN_12|GPIO_PIN_14, GPIO_PIN_SET);

  /*Configure GPIO pin Output Level */
  HAL_GPIO_WritePin(GPIOE, M1_IN1_Pin|M1_IN2_Pin|M2_IN1_Pin|GYRO2_CS_Pin, GPIO_PIN_RESET);

  /*Configure GPIO pins : PC13 M2_IN2_Pin M3_IN1_Pin M3_IN2_Pin
                           M4_IN1_Pin */
  GPIO_InitStruct.Pin = GPIO_PIN_13|M2_IN2_Pin|M3_IN1_Pin|M3_IN2_Pin
                          |M4_IN1_Pin;
  GPIO_InitStruct.Mode = GPIO_MODE_OUTPUT_PP;
  GPIO_InitStruct.Pull = GPIO_NOPULL;
  GPIO_InitStruct.Speed = GPIO_SPEED_FREQ_LOW;
  HAL_GPIO_Init(GPIOC, &GPIO_InitStruct);

  /*Configure GPIO pin : PA7 */
  GPIO_InitStruct.Pin = GPIO_PIN_7;
  GPIO_InitStruct.Mode = GPIO_MODE_OUTPUT_PP;
  GPIO_InitStruct.Pull = GPIO_PULLUP;
  GPIO_InitStruct.Speed = GPIO_SPEED_FREQ_VERY_HIGH;
  HAL_GPIO_Init(GPIOA, &GPIO_InitStruct);

  /*Configure GPIO pin : PC4 */
  GPIO_InitStruct.Pin = GPIO_PIN_4;
  GPIO_InitStruct.Mode = GPIO_MODE_OUTPUT_PP;
  GPIO_InitStruct.Pull = GPIO_PULLUP;
  GPIO_InitStruct.Speed = GPIO_SPEED_FREQ_VERY_HIGH;
  HAL_GPIO_Init(GPIOC, &GPIO_InitStruct);

  /*Configure GPIO pin : PB0 */
  GPIO_InitStruct.Pin = GPIO_PIN_0;
  GPIO_InitStruct.Mode = GPIO_MODE_OUTPUT_PP;
  GPIO_InitStruct.Pull = GPIO_NOPULL;
  GPIO_InitStruct.Speed = GPIO_SPEED_FREQ_LOW;
  HAL_GPIO_Init(GPIOB, &GPIO_InitStruct);

  /*Configure GPIO pins : PB1 PB12 PB14 */
  GPIO_InitStruct.Pin = GPIO_PIN_1|GPIO_PIN_12|GPIO_PIN_14;
  GPIO_InitStruct.Mode = GPIO_MODE_OUTPUT_PP;
  GPIO_InitStruct.Pull = GPIO_PULLUP;
  GPIO_InitStruct.Speed = GPIO_SPEED_FREQ_VERY_HIGH;
  HAL_GPIO_Init(GPIOB, &GPIO_InitStruct);

  /*Configure GPIO pins : M1_IN1_Pin M1_IN2_Pin M2_IN1_Pin GYRO2_CS_Pin */
  GPIO_InitStruct.Pin = M1_IN1_Pin|M1_IN2_Pin|M2_IN1_Pin|GYRO2_CS_Pin;
  GPIO_InitStruct.Mode = GPIO_MODE_OUTPUT_PP;
  GPIO_InitStruct.Pull = GPIO_NOPULL;
  GPIO_InitStruct.Speed = GPIO_SPEED_FREQ_LOW;
  HAL_GPIO_Init(GPIOE, &GPIO_InitStruct);

  /*Configure GPIO pin : PA8 */
  GPIO_InitStruct.Pin = GPIO_PIN_8;
  GPIO_InitStruct.Mode = GPIO_MODE_AF_PP;
  GPIO_InitStruct.Pull = GPIO_NOPULL;
  GPIO_InitStruct.Speed = GPIO_SPEED_FREQ_LOW;
  GPIO_InitStruct.Alternate = GPIO_AF0_MCO;
  HAL_GPIO_Init(GPIOA, &GPIO_InitStruct);

  /*Configure GPIO pin : GYRO1_CS_Pin */
  GPIO_InitStruct.Pin = GYRO1_CS_Pin;
  GPIO_InitStruct.Mode = GPIO_MODE_OUTPUT_PP;
  GPIO_InitStruct.Pull = GPIO_NOPULL;
  GPIO_InitStruct.Speed = GPIO_SPEED_FREQ_LOW;
  HAL_GPIO_Init(GYRO1_CS_GPIO_Port, &GPIO_InitStruct);

  /*AnalogSwitch Config */
  HAL_SYSCFG_AnalogSwitchConfig(SYSCFG_SWITCH_PC2, SYSCFG_SWITCH_PC2_CLOSE);

  /*AnalogSwitch Config */
  HAL_SYSCFG_AnalogSwitchConfig(SYSCFG_SWITCH_PC3, SYSCFG_SWITCH_PC3_CLOSE);

}

void StartDefaultTask(void *argument)
{
  /* init code for USB_DEVICE */
  MX_USB_DEVICE_Init();
  /* USER CODE BEGIN 5 */
#if APP_USE_VISION
  VisionTask(argument);      /* �����Լ����Ӿ��㷨 */
#else
  CamLcdTask(argument);      /* ԭ���̣�ֻ��ʾ����ͷ���棬������Ӳ�� */
#endif
  /* USER CODE END 5 */
}

void HAL_TIM_PeriodElapsedCallback(TIM_HandleTypeDef *htim)
{
  if (htim->Instance == TIM6)
  {
    HAL_IncTick();
  }
}

void Error_Handler(void)
{
  __disable_irq();
  while (1)
  {
  }
}
